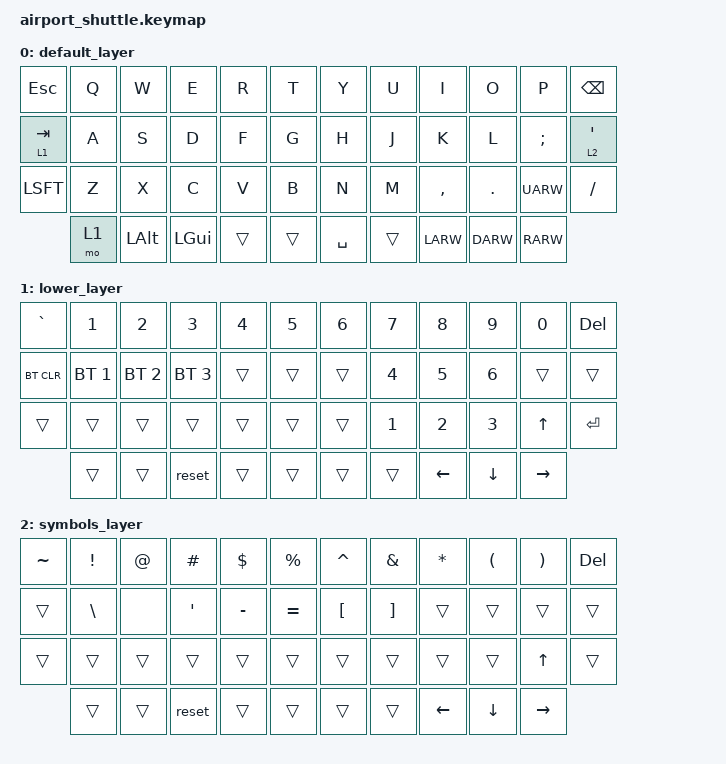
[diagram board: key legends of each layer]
#include <behaviors.dtsi>
#include <dt-bindings/zmk/keys.h>
#include <dt-bindings/zmk/bt.h>

/ {
  keymap {
    compatible = "zmk,keymap";

    default_layer {
// -----------------------------------------------------------------------------------------
// |  ESC  |  Q   |  W   |  E   |  R   |  T   |   Y   |  U    |  I   |  O   |   P   | BSPC  |
// |  TAB  |  A   |  S   |  D   |  F   |  G   |   H   |  J    |  K   |  L   |   ;   |  '    |
// | SHIFT |  Z   |  X   |  C   |  V   |  B   |   N   |  M    |  ,   |  .   |   /   |  RET  |
// | FN    | LGUI | LALT | LCTL | LOWR |     SPACE    |  RAIS | LARW | PRNTSCR | RGUI  |  RCTRL |
      bindings = <
  &kp ESC      &kp Q    &kp W &kp E &kp R &kp T  &kp Y   &kp U  &kp I    &kp O   &kp P    &kp BKSP
  &lt 1 TAB &kp A    &kp S &kp D &kp F &kp G  &kp H   &kp J  &kp K    &kp L   &kp SCLN &lt 2 QUOT
  &kp LSFT     &kp Z    &kp X &kp C &kp V &kp B  &kp N   &kp M  &kp CMMA &kp DOT &kp UARW &kp FSLH
  &mo 1     &kp LALT &kp LGUI &trans &trans &kp SPC &trans &kp LARW &kp DARW &kp RARW
      >;
    };

    lower_layer {
// -----------------------------------------------------------------------------------------
// |  `  |  1   |  2   |  3   |  4   |  5   |   6   |  7    |  8   |  9   |   0   | DEL  |
// |  BT CLEAR |  BT 1 |  BT 2  |  BT 3  |    |    |   |  4   |  5   |  6   |      |      |
// | SHIFT |  Z   |  X   |  C   |  V   |  B   |   N   |  M    |  ,   |  .   |   /   |  RET  |
// | FN    | LGUI | LALT | LCTL | LOWR |     SPACE    |  RAIS | LARW | PRNTSCR | RGUI  |  RCTRL |
      bindings = <
      &kp GRAVE &kp NUM_1 &kp NUM_2 &kp NUM_3 &kp NUM_4 &kp NUM_5 &kp NUM_6 &kp NUM_7 &kp NUM_8 &kp NUM_9 &kp NUM_0 &kp DEL
      &bt BT_CLR &bt BT_SEL 1 &bt BT_SEL 2 &bt BT_SEL 3 &trans &trans &trans &kp NUM_4 &kp NUM_5 &kp NUM_6 &trans &trans
      &trans &trans &trans &trans &trans &trans &trans &kp NUM_1 &kp NUM_2 &kp NUM_3 &kp UP &kp RET
      &trans &trans &reset &trans &trans &trans &trans &kp LEFT &kp DOWN 0 &kp RIGHT
      >;
    };
	
	 symbols_layer {
      bindings = <
      &kp TILDE &kp EXCL &kp AT &kp POUND &kp DLLR &kp PRCNT &kp CARET &kp AMPS &kp STAR &kp LPAR &kp RPAR &kp DEL
      &trans &kp BSLH & &kp QUOT &kp MINUS &kp EQUAL &kp LBKT &kp RBKT &trans &trans &trans &trans
      &trans &trans &trans &trans &trans &trans &trans &trans &trans &trans &kp UP &trans
      &trans &trans &reset &trans &trans &trans &trans &kp LEFT &kp DOWN &kp RIGHT
      >;
    };
  };
};

